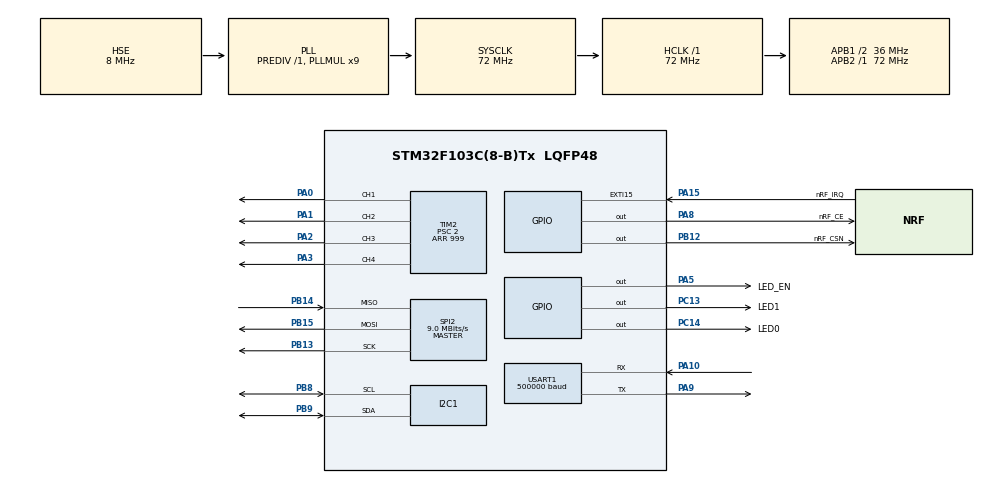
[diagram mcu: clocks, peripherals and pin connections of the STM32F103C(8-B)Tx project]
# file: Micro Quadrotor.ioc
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Dma.I2C1_RX.2.Direction=DMA_PERIPH_TO_MEMORY
Dma.I2C1_RX.2.Instance=DMA1_Channel7
Dma.I2C1_RX.2.MemDataAlignment=DMA_MDATAALIGN_BYTE
Dma.I2C1_RX.2.MemInc=DMA_MINC_ENABLE
Dma.I2C1_RX.2.Mode=DMA_CIRCULAR
Dma.I2C1_RX.2.PeriphDataAlignment=DMA_PDATAALIGN_BYTE
Dma.I2C1_RX.2.PeriphInc=DMA_PINC_DISABLE
Dma.I2C1_RX.2.Priority=DMA_PRIORITY_LOW
Dma.Request0=USART1_TX
Dma.Request1=USART1_RX
Dma.Request2=I2C1_RX
Dma.USART1_RX.1.Direction=DMA_PERIPH_TO_MEMORY
Dma.USART1_RX.1.Instance=DMA1_Channel5
Dma.USART1_RX.1.MemDataAlignment=DMA_MDATAALIGN_BYTE
Dma.USART1_RX.1.MemInc=DMA_MINC_ENABLE
Dma.USART1_RX.1.Mode=DMA_CIRCULAR
Dma.USART1_RX.1.PeriphDataAlignment=DMA_PDATAALIGN_BYTE
Dma.USART1_RX.1.PeriphInc=DMA_PINC_DISABLE
Dma.USART1_RX.1.Priority=DMA_PRIORITY_LOW
Dma.USART1_TX.0.Direction=DMA_MEMORY_TO_PERIPH
Dma.USART1_TX.0.Instance=DMA1_Channel4
Dma.USART1_TX.0.MemDataAlignment=DMA_MDATAALIGN_BYTE
Dma.USART1_TX.0.MemInc=DMA_MINC_ENABLE
Dma.USART1_TX.0.Mode=DMA_NORMAL
Dma.USART1_TX.0.PeriphDataAlignment=DMA_PDATAALIGN_BYTE
Dma.USART1_TX.0.PeriphInc=DMA_PINC_DISABLE
Dma.USART1_TX.0.Priority=DMA_PRIORITY_LOW
I2C1.I2C_Mode=I2C_Fast
Mcu.Family=STM32F1
Mcu.Name=STM32F103C(8-B)Tx
Mcu.Package=LQFP48
NVIC.DMA1_Channel4_IRQn=true\:0\:0\:false\:false\:true
NVIC.DMA1_Channel5_IRQn=true\:0\:0\:false\:false\:true
NVIC.DMA1_Channel7_IRQn=true\:0\:0\:false\:false\:true
NVIC.PriorityGroup=NVIC_PRIORITYGROUP_4
NVIC.USART1_IRQn=true\:0\:0\:false\:false\:true
PA0-WKUP.GPIO_Speed=GPIO_SPEED_HIGH
PA0-WKUP.Signal=S_TIM2_CH1_ETR
PA1.GPIO_Speed=GPIO_SPEED_HIGH
PA1.Signal=S_TIM2_CH2
PA10.Mode=Asynchronous
PA10.Signal=USART1_RX
PA13.Mode=Serial_Wire
PA13.Signal=SYS_JTMS-SWDIO
PA14.Mode=Serial_Wire
PA14.Signal=SYS_JTCK-SWCLK
PA15.GPIO_Label=nRF_IRQ
PA15.Signal=GPXTI15
PA2.Signal=S_TIM2_CH3
PA3.Signal=S_TIM2_CH4
PA5.GPIO_Label=LED_EN
PA5.Signal=GPIO_Output
PA8.GPIO_Label=nRF_CE
PA8.Signal=GPIO_Output
PA9.Mode=Asynchronous
PA9.Signal=USART1_TX
PB12.GPIO_Label=nRF_CSN
PB12.Signal=GPIO_Output
PB13.Mode=Full_Duplex_Master
PB13.Signal=SPI2_SCK
PB14.Mode=Full_Duplex_Master
PB14.Signal=SPI2_MISO
PB15.Mode=Full_Duplex_Master
PB15.Signal=SPI2_MOSI
PB8.Mode=I2C
PB8.Signal=I2C1_SCL
PB9.Mode=I2C
PB9.Signal=I2C1_SDA
PC13-TAMPER-RTC.GPIO_Label=LED1
PC13-TAMPER-RTC.Signal=GPIO_Output
PC14-OSC32_IN.GPIO_Label=LED0
PC14-OSC32_IN.Signal=GPIO_Output
PD0-OSC_IN.Mode=HSE-External-Oscillator
PD0-OSC_IN.Signal=RCC_OSC_IN
PD1-OSC_OUT.Mode=HSE-External-Oscillator
PD1-OSC_OUT.Signal=RCC_OSC_OUT
ProjectManager.HeapSize=0x200
ProjectManager.StackSize=0x400
ProjectManager.TargetToolchain=EWARM
RCC.ADCPresc=RCC_ADCPCLK2_DIV6
RCC.AHBFreq_Value=72000000
RCC.APB1CLKDivider=RCC_HCLK_DIV2
RCC.APB1Freq_Value=36000000
RCC.APB1TimFreq_Value=72000000
RCC.APB2Freq_Value=72000000
RCC.APB2TimFreq_Value=72000000
RCC.HCLKFreq_Value=72000000
RCC.HSIState=RCC_HSI_ON
RCC.PLLMUL=RCC_PLL_MUL9
RCC.PLLSourceVirtual=RCC_PLLSOURCE_HSE
RCC.SYSCLKFreq_VALUE=72000000
RCC.SYSCLKSource=RCC_SYSCLKSOURCE_PLLCLK
RCC.USBFreq_Value=72000000
SH.S_TIM2_CH1_ETR.0=TIM2_CH1,PWM Generation1 CH1
SH.S_TIM2_CH2.0=TIM2_CH2,PWM Generation2 CH2
SH.S_TIM2_CH3.0=TIM2_CH3,PWM Generation3 CH3
SH.S_TIM2_CH4.0=TIM2_CH4,PWM Generation4 CH4
SPI2.BaudRatePrescaler=SPI_BAUDRATEPRESCALER_4
SPI2.CalculateBaudRate=9.0 MBits/s
SPI2.Mode=SPI_MODE_MASTER
SPI2.NSS=SPI_NSS_SOFT
TIM2.Channel-PWM\ Generation2\ CH2=TIM_CHANNEL_2
TIM2.Channel-PWM\ Generation3\ CH3=TIM_CHANNEL_3
TIM2.Channel-PWM\ Generation4\ CH4=TIM_CHANNEL_4
TIM2.OCFastMode_PWM-PWM\ Generation1\ CH1=TIM_OCFAST_DISABLE
TIM2.OCFastMode_PWM-PWM\ Generation2\ CH2=TIM_OCFAST_DISABLE
TIM2.Period=999
TIM2.Prescaler=2
TIM2.Pulse-PWM\ Generation1\ CH1=0
TIM2.Pulse-PWM\ Generation2\ CH2=0
TIM2.TIM_MasterOutputTrigger=TIM_TRGO_RESET
USART1.BaudRate=500000
VP_TIM2_VS_ClockSourceINT.Mode=Internal
board=Micro Quadrotor

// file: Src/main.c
/**
  ******************************************************************************
  * File Name          : main.c
  * Description        : Main program body
  ******************************************************************************
  *
  * COPYRIGHT(c) 2016 STMicroelectronics
  *
  * Redistribution and use in source and binary forms, with or without modification,
  * are permitted provided that the following conditions are met:
  *   1. Redistributions of source code must retain the above copyright notice,
  *      this list of conditions and the following disclaimer.
  *   2. Redistributions in binary form must reproduce the above copyright notice,
  *      this list of conditions and the following disclaimer in the documentation
  *      and/or other materials provided with the distribution.
  *   3. Neither the name of STMicroelectronics nor the names of its contributors
  *      may be used to endorse or promote products derived from this software
  *      without specific prior written permission.
  *
  * THIS SOFTWARE IS PROVIDED BY THE COPYRIGHT HOLDERS AND CONTRIBUTORS "AS IS"
  * AND ANY EXPRESS OR IMPLIED WARRANTIES, INCLUDING, BUT NOT LIMITED TO, THE
  * IMPLIED WARRANTIES OF MERCHANTABILITY AND FITNESS FOR A PARTICULAR PURPOSE ARE
  * DISCLAIMED. IN NO EVENT SHALL THE COPYRIGHT HOLDER OR CONTRIBUTORS BE LIABLE
  * FOR ANY DIRECT, INDIRECT, INCIDENTAL, SPECIAL, EXEMPLARY, OR CONSEQUENTIAL
  * DAMAGES (INCLUDING, BUT NOT LIMITED TO, PROCUREMENT OF SUBSTITUTE GOODS OR
  * SERVICES; LOSS OF USE, DATA, OR PROFITS; OR BUSINESS INTERRUPTION) HOWEVER
  * CAUSED AND ON ANY THEORY OF LIABILITY, WHETHER IN CONTRACT, STRICT LIABILITY,
  * OR TORT (INCLUDING NEGLIGENCE OR OTHERWISE) ARISING IN ANY WAY OUT OF THE USE
  * OF THIS SOFTWARE, EVEN IF ADVISED OF THE POSSIBILITY OF SUCH DAMAGE.
  *
  ******************************************************************************
  */
#include "stm32f1xx_hal.h"
#include "dma.h"
#include "i2c.h"
#include "spi.h"
#include "tim.h"
#include "usart.h"
#include "gpio.h"

/* USER CODE BEGIN Includes */
#include "Quad_Config.h"
using namespace Quad;
/* USER CODE END Includes */

/* USER CODE BEGIN PV */
/* Private variables ---------------------------------------------------------*/

/* USER CODE END PV */

void SystemClock_Config(void);

/* USER CODE BEGIN PFP */
/* Private function prototypes -----------------------------------------------*/

/* USER CODE END PFP */

int main(void)
{

  /* MCU Configuration----------------------------------------------------------*/

  /* Reset of all peripherals, Initializes the Flash interface and the Systick. */
  HAL_Init();

  /* Configure the system clock */
  SystemClock_Config();

  /* Initialize all configured peripherals */
  MX_GPIO_Init();
  MX_DMA_Init();
  MX_I2C1_Init();
  MX_SPI2_Init();
  MX_TIM2_Init();
  MX_USART1_UART_Init();

  /* USER CODE BEGIN 2 */
  quadrotor.Init();
  quadrotor.Fly();

  /* USER CODE END 2 */

  /* Infinite loop */
  while (1)
  {

  }

}

/** System Clock Configuration
*/
void SystemClock_Config(void)
{

  RCC_OscInitTypeDef RCC_OscInitStruct;
  RCC_ClkInitTypeDef RCC_ClkInitStruct;

  RCC_OscInitStruct.OscillatorType = RCC_OSCILLATORTYPE_HSE;
  RCC_OscInitStruct.HSEState = RCC_HSE_ON;
  RCC_OscInitStruct.HSEPredivValue = RCC_HSE_PREDIV_DIV1;
  RCC_OscInitStruct.PLL.PLLState = RCC_PLL_ON;
  RCC_OscInitStruct.PLL.PLLSource = RCC_PLLSOURCE_HSE;
  RCC_OscInitStruct.PLL.PLLMUL = RCC_PLL_MUL9;
  HAL_RCC_OscConfig(&RCC_OscInitStruct);

  RCC_ClkInitStruct.ClockType = RCC_CLOCKTYPE_HCLK|RCC_CLOCKTYPE_SYSCLK
                              |RCC_CLOCKTYPE_PCLK1|RCC_CLOCKTYPE_PCLK2;
  RCC_ClkInitStruct.SYSCLKSource = RCC_SYSCLKSOURCE_PLLCLK;
  RCC_ClkInitStruct.AHBCLKDivider = RCC_SYSCLK_DIV1;
  RCC_ClkInitStruct.APB1CLKDivider = RCC_HCLK_DIV2;
  RCC_ClkInitStruct.APB2CLKDivider = RCC_HCLK_DIV1;
  HAL_RCC_ClockConfig(&RCC_ClkInitStruct, FLASH_LATENCY_2);

  HAL_SYSTICK_Config(HAL_RCC_GetHCLKFreq()/1000);

  HAL_SYSTICK_CLKSourceConfig(SYSTICK_CLKSOURCE_HCLK);

  /* SysTick_IRQn interrupt configuration */
  HAL_NVIC_SetPriority(SysTick_IRQn, 0, 0);
}

/************************ (C) COPYRIGHT STMicroelectronics *****END OF FILE****/
